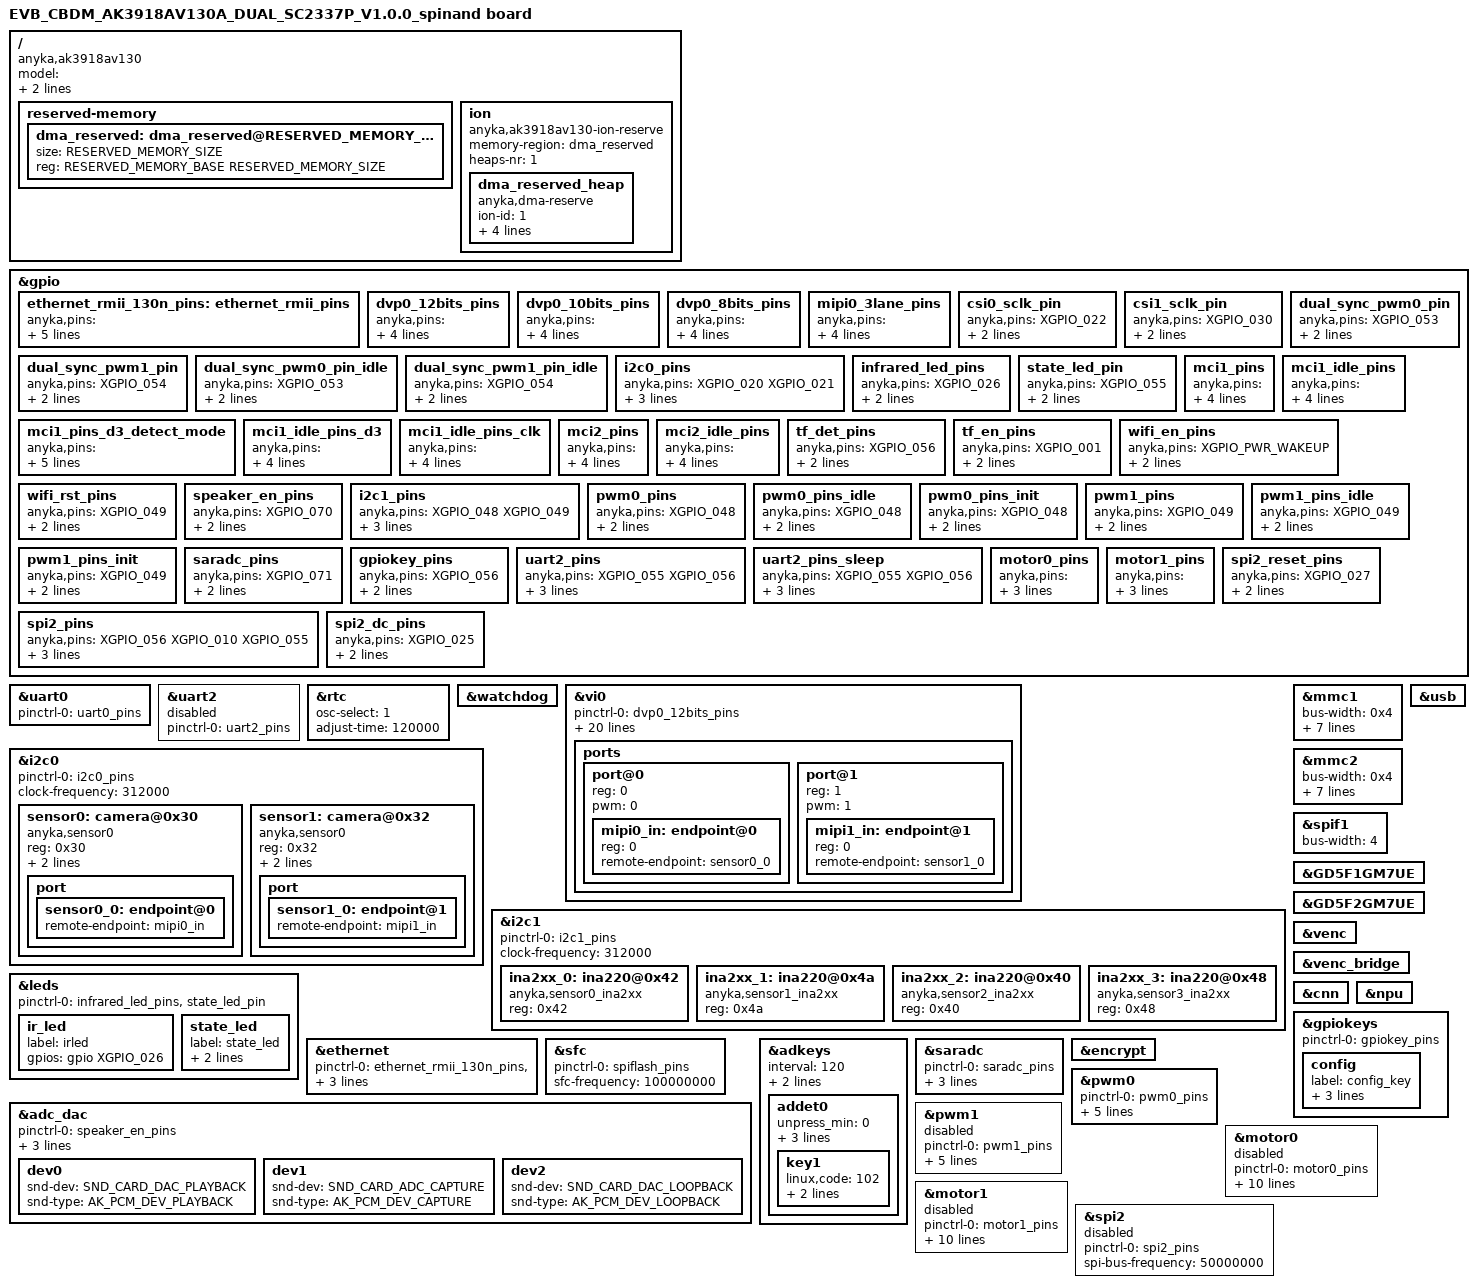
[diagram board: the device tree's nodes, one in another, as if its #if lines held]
/*
 * AK3918AV130 dev board dts
 *
 * Copyright (C) 2020 Anyka(Guangzhou) Microelectronics Technology Co., Ltd.
 *
 * This program is free software; you can redistribute it and/or modify
 * it under the terms of the GNU General Public License as published by
 * the Free Software Foundation; either version 2 of the License, or
 * (at your option) any later version.
 *
 * This program is distributed in the hope that it will be useful,
 * but WITHOUT ANY WARRANTY; without even the implied warranty of
 * MERCHANTABILITY or FITNESS FOR A PARTICULAR PURPOSE.  See the
 * GNU General Public License for more details.
 */

#include "anycloud_ak3918av130.dtsi"
//#include "anycloud_norflash.dtsi"
#include "anycloud_nandflash.dtsi"

#ifdef RESERVED_MEMORY_SIZE
#undef RESERVED_MEMORY_SIZE
#endif

#define RESERVED_MEMORY_SIZE  0x1C00000   /* 28MB*/

/ {
    compatible = "anyka,ak3918av130";
    model = "EVB_CBDM_AK3918AV130A_DUAL_SC2337P_V1.0.0_spinand board";
    version = "V1.0.00";

    reserved-memory {
        #address-cells = <1>;
        #size-cells = <1>;
        ranges;

        dma_reserved: dma_reserved@RESERVED_MEMORY_BASE {
            /*compatible = "shared-dma-pool";*/
            /*linux,cma-default;*/
            /*reusable;*/
            size = <RESERVED_MEMORY_SIZE>;
            reg = <RESERVED_MEMORY_BASE RESERVED_MEMORY_SIZE>;
            status = "okay";
        };

    };

    ion {
        compatible = "anyka,ak3918av130-ion-reserve";
        memory-region = <&dma_reserved>;
        #address-cells = <1>;
        #size-cells = <1>;
        heaps-nr = <1>;
        ranges;

        dma_reserved_heap: dma_reserved_heap {
            compatible = "anyka,dma-reserve";
            ion-id = <1>;
            /* ion-type: 0 = cma ; 1 = prereserved memory which kernel do not  aware of */
            ion-type = <1>;
            base-address = <RESERVED_MEMORY_BASE>;
            size = <RESERVED_MEMORY_SIZE>;
            align = <0x4>;
            status = "okay";
        };
    };
};

&gpio {
    /*
    * "anyka,function": func index, please refer to dt-bindings/pinctrl/ak3918av130_pinctrl.h
    * "anyka,pull": configuration of the pins
    * bit[7:0]: pull up/down configuration
    *     bit[0]: pull up or pull down selection, 1 means select pull down, 0 means select pull up
    *     bit[4]: pull up or pull down enable, 1 means enable pull up&down function, 0 means disable fuction
    * !!! Notice that not all pin support pull up and pull down. Please refer to the programer's guide.
    * bit[11:8]: driver strength configuration.
    *     bit[9:8] drive strength.
    * bit[12:15] gpio direction
    *     bit[12]: direction. 0 is output, 1 is input
    *     bit[15]: enable direction. 1 is enable
    * bit[19:16]: input enable configuration
    *     bit[16]: 1 means enable input, 0 means disable input.
    * bit[20-23]: gpio output level
    *     bit[20]: 0 is low level, 1 is high level
    *     bit[23]: enable gpio output level. 1 is enable
    * bit[31:24]: pin slew rate configuration
    *     bit[24]: 1 means enable slew rate, 0 means disable slew rate.
    * !!! Notice OTHER bits which not mentioned please set to 0.
    */

    ethernet_rmii_130n_pins: ethernet_rmii_pins {
        anyka,pins = <  XGPIO_003
                        XGPIO_005
                        XGPIO_002
                        XGPIO_011
                        XGPIO_006
                        XGPIO_000
                        XGPIO_007
                        XGPIO_008
                        XGPIO_004>;
        anyka,function = <  XGPIO_003_FUNC_RMII_MDIO
                            XGPIO_005_FUNC_RMII_MDC
                            XGPIO_002_FUNC_RMII_RXDV
                            XGPIO_011_FUNC_RMII_RXD0
                            XGPIO_006_FUNC_RMII_RXD1
                            XGPIO_000_FUNC_OPCLK1
                            XGPIO_007_FUNC_RMII_TXD0
                            XGPIO_008_FUNC_RMII_TXD1
                            XGPIO_004_FUNC_RMII_TXEN
                            >;
      anyka,pull = < 0x00010010 /* XGPIO_003_FUNC_RMII_MDIO, input enable, driver 2mA, slow slew rate, pull up enable*/
                     0x00010011 /* XGPIO_005_FUNC_RMII_MDC,  input enable, driver 2mA, slow slew rate, pull down enable*/
                     0x00010011 /* XGPIO_002_FUNC_RMII_RXDV, input enable, driver 2mA, slow slew rate, pull down enable*/
                     0x00010011 /* XGPIO_011_FUNC_RMII_RXD0, input enable, driver 2mA, slow slew rate, pull down enable*/
                     0x00010011 /* XGPIO_006_FUNC_RMII_RXD1, input enable, driver 2mA, slow slew rate, pull down enable*/ 
                     0x00010200 /* XGPIO_000_FUNC_OPCLK1,    input enable, driver 4mA, slow slew rate, pull up disable and pull down disable*/ 
                     0x01010011 /* XGPIO_007_FUNC_RMII_TXD0, input enable, driver 2mA, fast slew rate, pull down enable*/ 
                     0x01010011 /* XGPIO_008_FUNC_RMII_TXD1, input enable, driver 2mA, fast slew rate, pull down enable*/ 
                     0x00010011 /* XGPIO_004_FUNC_RMII_TXEN, input enable, driver 2mA, slow slew rate, pull down enable*/ 
                    >;
    };

    dvp0_12bits_pins: dvp0_12bits_pins {
        anyka,pins = <XGPIO_022
                         XGPIO_100
                         XGPIO_009
                         XGPIO_010
                         XGPIO_017
                         XGPIO_018
                         XGPIO_019
                         XGPIO_020
                         XGPIO_023
                         XGPIO_021
                         XGPIO_022
                         XGPIO_099
                         XGPIO_102
                         XGPIO_101
                         XGPIO_078
                         XGPIO_079>;
        anyka,function = <XGPIO_022_FUNC_CSI0_SCLK
                            XGPIO_100_FUNC_CSI_CLK
                            XGPIO_009_FUNC_CSI_HSYNC
                            XGPIO_010_FUNC_CSI_VSYNC
                            XGPIO_017_FUNC_CSI_D0
                            XGPIO_018_FUNC_CSI_D1
                            XGPIO_019_FUNC_CSI_D2
                            XGPIO_020_FUNC_CSI_D3
                            XGPIO_023_FUNC_CSI_D4
                            XGPIO_021_FUNC_CSI_D5
                            XGPIO_022_FUNC_CSI_D6
                            XGPIO_099_FUNC_CSI_D7
                            XGPIO_102_FUNC_CSI_D8
                            XGPIO_101_FUNC_CSI_D9
                            XGPIO_078_FUNC_CSI_D10
                            XGPIO_079_FUNC_CSI_D11>;
        anyka,pull = <0x00010010>;
    };

    dvp0_10bits_pins: dvp0_10bits_pins {
        anyka,pins = <XGPIO_100		//pclk
                         XGPIO_009	//hsync
                         XGPIO_010	//vsync
                         XGPIO_019	//d2
                         XGPIO_020	//d3
                         XGPIO_023	//d4
                         XGPIO_021	//d5
                         XGPIO_022	//d6
                         XGPIO_099	//d7
                         XGPIO_102	//d8
                         XGPIO_101	//d9
                         XGPIO_078	//d10
                         XGPIO_079>;//d11
        anyka,function = <XGPIO_100_FUNC_CSI_CLK
                            XGPIO_009_FUNC_CSI_HSYNC
                            XGPIO_010_FUNC_CSI_VSYNC
                            XGPIO_019_FUNC_CSI_D2
                            XGPIO_020_FUNC_CSI_D3
                            XGPIO_023_FUNC_CSI_D4
                            XGPIO_021_FUNC_CSI_D5
                            XGPIO_022_FUNC_CSI_D6
                            XGPIO_099_FUNC_CSI_D7
                            XGPIO_102_FUNC_CSI_D8
                            XGPIO_101_FUNC_CSI_D9
                            XGPIO_078_FUNC_CSI_D10
                            XGPIO_079_FUNC_CSI_D11>;
        anyka,pull = <0x00010010>;
    };

    dvp0_8bits_pins: dvp0_8bits_pins {
        anyka,pins = <XGPIO_022
                         XGPIO_100
                         XGPIO_009
                         XGPIO_010
                         XGPIO_017
                         XGPIO_018
                         XGPIO_019
                         XGPIO_020
                         XGPIO_023
                         XGPIO_021
                         XGPIO_022
                         XGPIO_099>;
        anyka,function = <XGPIO_022_FUNC_CSI0_SCLK
                            XGPIO_100_FUNC_CSI_CLK
                            XGPIO_009_FUNC_CSI_HSYNC
                            XGPIO_010_FUNC_CSI_VSYNC
                            XGPIO_017_FUNC_CSI_D0
                            XGPIO_018_FUNC_CSI_D1
                            XGPIO_019_FUNC_CSI_D2
                            XGPIO_020_FUNC_CSI_D3
                            XGPIO_023_FUNC_CSI_D4
                            XGPIO_021_FUNC_CSI_D5
                            XGPIO_022_FUNC_CSI_D6
                            XGPIO_099_FUNC_CSI_D7>;
        anyka,pull = <0x00010010>;
    };

    mipi0_3lane_pins: mipi0_3lane_pins {
        anyka,pins = <XGPIO_099
                        XGPIO_100
                        XGPIO_078
                        XGPIO_079
                        XGPIO_101
                        XGPIO_102>;
        anyka,function = <XGPIO_099_FUNC_MIPI_RX_L0P
                            XGPIO_100_FUNC_MIPI_RX_L0N
                            XGPIO_078_FUNC_MIPI_RX_L1P
                            XGPIO_079_FUNC_MIPI_RX_L1N
                            XGPIO_101_FUNC_MIPI_RX_L2P
                            XGPIO_102_FUNC_MIPI_RX_L2N>;
        anyka,pull = <0x00010010>;
    };

    csi0_sclk_pin: csi0_sclk_pin {
        anyka,pins = <XGPIO_022>;
        anyka,function = <XGPIO_022_FUNC_CSI0_SCLK>;
        anyka,pull = <0x00010010>;
    };

    csi1_sclk_pin: csi1_sclk_pin {
        anyka,pins = <XGPIO_030>;
        anyka,function = <XGPIO_030_FUNC_CSI1_SCLK>;
        anyka,pull = <0x00010010>;
    };

    dual_sync_pwm0_pin: dual_sync_pwm0_pin {
        anyka,pins = <XGPIO_053>;
        anyka,function = <XGPIO_053_FUNC_PWM_CSI0>;
        anyka,pull = <0x01000000>;
    };

    dual_sync_pwm1_pin: dual_sync_pwm1_pin {
        anyka,pins = <XGPIO_054>;
        anyka,function = <XGPIO_054_FUNC_PWM_CSI1>;
        anyka,pull = <0x01000000>;
    };

    dual_sync_pwm0_pin_idle: dual_sync_pwm0_pin_idle {
        anyka,pins = <XGPIO_053>;
        anyka,function = <XGPIO_053_FUNC_GPIO53>;
        anyka,pull = <0x00008011>;
    };

    dual_sync_pwm1_pin_idle: dual_sync_pwm1_pin_idle {
        anyka,pins = <XGPIO_054>;
        anyka,function = <XGPIO_054_FUNC_GPIO54>;
        anyka,pull = <0x00008011>;
    };

    i2c0_pins: i2c0_pins {
        anyka,pins = <XGPIO_020 XGPIO_021>;
        anyka,function = <XGPIO_020_FUNC_TWI0_SDA XGPIO_021_FUNC_TWI0_SCL>;
        anyka,pull = <0x10010>;
    };

    infrared_led_pins: infrared_led_pins {
        anyka,pins = <XGPIO_026>;
        anyka,function = <XGPIO_026_FUNC_GPIO26>;
        anyka,pull = <0x10>;
    };

    state_led_pin: state_led_pin {
        anyka,pins = <XGPIO_055>;
        anyka,function = <XGPIO_055_FUNC_GPIO55>;
        anyka,pull = <0x10>;
    };

    mci1_pins: mci1_pins {
        anyka,pins = <XGPIO_036
                        XGPIO_035
                        XGPIO_034
                        XGPIO_033
                        XGPIO_032
                        XGPIO_031>;
        anyka,function = <XGPIO_036_FUNC_SDIO0_DATA1
                            XGPIO_035_FUNC_SDIO0_DATA0
                            XGPIO_034_FUNC_SDIO0_MCLK
                            XGPIO_033_FUNC_SDIO0_CMD
                            XGPIO_032_FUNC_SDIO0_DATA3
                            XGPIO_031_FUNC_SDIO0_DATA2>;
        anyka,pull = <0x10010>;
    };

    /*
       when not use tf card, set to idle state,
       to protect tf card and extend it's life.
    */
    mci1_idle_pins: mci1_idle_pins {
        anyka,pins = <XGPIO_036
                        XGPIO_035
                        XGPIO_034
                        XGPIO_033
                        XGPIO_032
                        XGPIO_031>;
        anyka,function = <XGPIO_036_FUNC_GPIO36
                            XGPIO_035_FUNC_GPIO35
                            XGPIO_034_FUNC_GPIO34
                            XGPIO_033_FUNC_GPIO33
                            XGPIO_032_FUNC_GPIO32
                            XGPIO_031_FUNC_GPIO31>;
        anyka,pull = <0x11>;
    };

    /* 
     *  When using DATA3 as plugin and plugoff detect:
     *  1. Set XGPIO_032_FUNC_SDIO0_DATA3 pull up disable and pull down disable
     *  2. Using PULLDOWN RESISTANCE on PCB, for example, 510   KΩ.
     */
    mci1_pins_d3_detect_mode: mci1_pins_d3_detect_mode {
        anyka,pins = <XGPIO_036
                        XGPIO_035
                        XGPIO_034
                        XGPIO_033
                        XGPIO_032
                        XGPIO_031>;
        anyka,function = <XGPIO_036_FUNC_SDIO0_DATA1
                            XGPIO_035_FUNC_SDIO0_DATA0
                            XGPIO_034_FUNC_SDIO0_MCLK
                            XGPIO_033_FUNC_SDIO0_CMD
                            XGPIO_032_FUNC_SDIO0_DATA3
                            XGPIO_031_FUNC_SDIO0_DATA2>;
        anyka,pull = <  0x10010 
                        0x10010
                        0x10010
                        0x10010
                        0x10001  /* disable pull down and pull up */
                        0x10010 >;
    };

    /*
       when not use tf card, set to idle state, the pin set to gpio function except dat3 pin.
       to protect tf card, extend it's life.
    */
    mci1_idle_pins_d3: mci1_idle_pins_d3 {
        anyka,pins = <XGPIO_036
                        XGPIO_035
                        XGPIO_034
                        XGPIO_033
                        XGPIO_032
                        XGPIO_031>;
        anyka,function = <XGPIO_036_FUNC_GPIO36
                            XGPIO_035_FUNC_GPIO35
                            XGPIO_034_FUNC_GPIO34
                            XGPIO_033_FUNC_GPIO33
                            XGPIO_032_FUNC_SDIO0_DATA3
                            XGPIO_031_FUNC_GPIO31>;
        anyka,pull = <  0x11
                        0x11
                        0x11
                        0x11
                        0x10001  /* disable pull down and pull up */
                        0x11 >;
    };

    /*
       when not use tf card, set to idle state, the pin set to gpio function except mclk pin.
       to protect tf card, extend it's life.
    */
    mci1_idle_pins_clk: mci1_idle_pins_clk {
        anyka,pins = <XGPIO_036
                        XGPIO_035
                        XGPIO_034
                        XGPIO_033
                        XGPIO_032
                        XGPIO_031>;
        anyka,function = <XGPIO_036_FUNC_GPIO36
                            XGPIO_035_FUNC_GPIO35
                            XGPIO_034_FUNC_SDIO0_MCLK
                            XGPIO_033_FUNC_GPIO33
                            XGPIO_032_FUNC_GPIO32
                            XGPIO_031_FUNC_GPIO31>;
        anyka,pull = <  0x11
                        0x11
                        0x10010 /* clk */
                        0x11
                        0x11
                        0x11 >;
    };

    mci2_pins: mci2_pins {
        anyka,pins = <XGPIO_058
                     XGPIO_065
                     XGPIO_066
                     XGPIO_067
                     XGPIO_068
                     XGPIO_069>;
        anyka,function = <  XGPIO_058_FUNC_SDIO1_CMD
                        XGPIO_065_FUNC_SDIO1_MCLK
                        XGPIO_066_FUNC_SDIO1_DATA2
                        XGPIO_067_FUNC_SDIO1_DATA3
                        XGPIO_068_FUNC_SDIO1_DATA0
                        XGPIO_069_FUNC_SDIO1_DATA1>;
        anyka,pull = <0x10010>;
    };

    mci2_idle_pins: mci2_idle_pins {
        anyka,pins = <  XGPIO_058
                        XGPIO_065
                        XGPIO_066
                        XGPIO_067
                        XGPIO_068
                        XGPIO_069>;
        anyka,function = <  XGPIO_058_FUNC_GPIO58
                            XGPIO_065_FUNC_GPIO65
                            XGPIO_066_FUNC_GPIO66
                            XGPIO_067_FUNC_GPIO67
                            XGPIO_068_FUNC_GPIO68
                            XGPIO_069_FUNC_GPIO69>;
        anyka,pull = <0x0>;

    };

    tf_det_pins: tf_det_pins {
        anyka,pins = <XGPIO_056>;
        anyka,function = <XGPIO_056_FUNC_GPIO56>;
        anyka,pull = <0x10010>;
    };

    tf_en_pins: tf_en_pins {
        anyka,pins = <XGPIO_001>;
        anyka,function = <XGPIO_001_FUNC_GPIO1>;
        anyka,pull = <0x10010>;
    };

    wifi_en_pins: wifi_en_pins {
        anyka,pins = <XGPIO_PWR_WAKEUP>;
        anyka,function = <XGPIO_081_FUNC_GPIO81>;
        anyka,pull = <0x10010>;
    };

    wifi_rst_pins: wifi_rst_pins {
        anyka,pins = <XGPIO_049>;
        anyka,function = <XGPIO_049_FUNC_GPIO49>;
        anyka,pull = <0x10010>;
    };

    speaker_en_pins: speaker_en_pins {
        anyka,pins = <XGPIO_070>;
        anyka,function = <XGPIO_070_FUNC_GPIO70>;
        anyka,pull = <0x00808000>;
    };

    i2c1_pins: i2c1_pins {
        anyka,pins = <XGPIO_048 XGPIO_049>;
        anyka,function = <XGPIO_048_FUNC_TWI1_SCL XGPIO_049_FUNC_TWI1_SDA>;
        anyka,pull = <0x10010>;
    };

    pwm0_pins: pwm0_pins {
        anyka,pins = <XGPIO_048>;
        anyka,function = <XGPIO_048_FUNC_PWM0>;
        anyka,pull = <0x1000010>;
    };

    pwm0_pins_idle: pwm0_pins_idle {
        anyka,pins = <XGPIO_048>;
        anyka,function = <XGPIO_048_FUNC_GPIO48>;
        anyka,pull = <0x00808000>;
    };

    pwm0_pins_init: pwm0_pins_init {
        anyka,pins = <XGPIO_048>;
        anyka,function = <XGPIO_048_FUNC_GPIO48>;
        anyka,pull = <0x00019010>;
    };

    pwm1_pins: pwm1_pins {
        anyka,pins = <XGPIO_049>;
        anyka,function = <XGPIO_049_FUNC_PWM1>;
        anyka,pull = <0x1000010>;
    };

    pwm1_pins_idle: pwm1_pins_idle {
        anyka,pins = <XGPIO_049>;
        anyka,function = <XGPIO_049_FUNC_GPIO49>;
        anyka,pull = <0x00808000>;
    };

    pwm1_pins_init: pwm1_pins_init {
        anyka,pins = <XGPIO_049>;
        anyka,function = <XGPIO_049_FUNC_GPIO49>;
        anyka,pull = <0x00019010>;
    };

    saradc_pins: saradc_pins {
        anyka,pins = <XGPIO_071>;
        anyka,function = <XGPIO_071_FUNC_AIN0>;
        anyka,pull = <0x0000000>;
    };

	gpiokey_pins:gpiokey_pins {
		anyka,pins = <XGPIO_056>;
		anyka,function = <XGPIO_056_FUNC_GPIO56>;
		anyka,pull = <0x00010010>;
	};

    uart2_pins: uart2_pins {
        /* uart1 without flow control */
        anyka,pins = <XGPIO_055 XGPIO_056>;
        anyka,function = <XGPIO_055_FUNC_UART2_RXD XGPIO_056_FUNC_UART2_TXD>;
        anyka,pull = <0x00010010 0x00010010>;
    };

    uart2_pins_sleep: uart2_pins_sleep {
        /* uart1 without flow control */
        anyka,pins = <XGPIO_055 XGPIO_056>;
        anyka,function = <XGPIO_055_FUNC_GPIO55 XGPIO_056_FUNC_GPIO56>;
        anyka,pull = <0x00000000>;
    };

    /* function: 0 means gpio */
    motor0_pins: motor0_pins {
        anyka,pins = <XGPIO_048 XGPIO_049 XGPIO_003 XGPIO_002>;
        anyka,function = <0>;
        anyka,pull = <0x00000010>;
    };

    motor1_pins: motor1_pins {
        anyka,pins = <XGPIO_001 XGPIO_000 XGPIO_055 XGPIO_056>;
        anyka,function = <0>;
        anyka,pull = <0x00000010>;
    };

    spi2_pins: spi2_pins {
        anyka,pins = <XGPIO_056 XGPIO_010 XGPIO_055>;
        anyka,function = <XGPIO_056_FUNC_SPI2_CLK XGPIO_010_FUNC_SPI2_DOUT XGPIO_055_FUNC_SPI2_CS0>;
        anyka,pull = <0x00010000>;
    };
    
    spi2_reset_pins: spi2_reset_pins {
        anyka,pins = <XGPIO_027>;
        anyka,function = <XGPIO_027_FUNC_GPIO27>;
        anyka,pull = <0x00010010>;
    };
    
    spi2_dc_pins: spi2_dc_pins {
        anyka,pins = <XGPIO_025>;
        anyka,function = <XGPIO_025_FUNC_GPIO25>;
        anyka,pull = <0x00010010>;
    };
    
};

&uart0 {
    pinctrl-names = "default";
    pinctrl-0 = <&uart0_pins>;
    status = "okay";
};

&uart2 {
    pinctrl-names = "default";
    pinctrl-0 = <&uart2_pins>;
    status = "disable";
};

&rtc {
    /*
     * rtc osc-select, 1 means INTERNAL RC OSC, 0 means EXTERNAL XTAL
     * if internal RC OSC is used to generate 32KH,time adjustment should be setting.(basic unit: ms)
     * AV100P/X only support internal RC OSC.
     */
    osc-select = <1>;
    adjust-time = <120000>;//校准间隔时间单位ms
    status = "okay";
};


&watchdog {
    status = "okay";
};

&vi0{
    pinctrl-names = "dvp0_12bits", "dvp0_10bits", "dvp0_8bits",
                    /*
                    * "mipi0_2lane", "mipi0_1lane",
                    */
                    "csi0_sclk", "csi1_sclk",
                    "pwm0", "pwm1",
                    "pwm0_idle", "pwm1_idle";
    pinctrl-0 = <&dvp0_12bits_pins>;
    pinctrl-1 = <&dvp0_10bits_pins>;
    pinctrl-2 = <&dvp0_8bits_pins>;
    pinctrl-3 = <&csi0_sclk_pin>;
    pinctrl-4 = <&csi1_sclk_pin>;
    pinctrl-5 = <&dual_sync_pwm0_pin>;
    pinctrl-6 = <&dual_sync_pwm1_pin>;
	pinctrl-7 = <&dual_sync_pwm0_pin_idle>;
	pinctrl-8 = <&dual_sync_pwm1_pin_idle>;

	/*
    pinctrl-5 = <&mipi0_2lane_pins>;
    pinctrl-6 = <&mipi0_1lane_pins>;
	*/
    status = "okay";

	csi_mipi_lane_swap = <
		SENSOR_D0	//L0
		SENSOR_C0	//L1
		SENSOR_D1	//L2
        SENSOR_D2   //L3
        SENSOR_C1   //L4
        SENSOR_D3   //L5
		>;//MIPI_RX_L0~2.
	csi_mipi_dndp_swap = <
		MIPI_DNDP_NOSWAP	//L0
		MIPI_DNDP_NOSWAP	//L1
		MIPI_DNDP_NOSWAP	//L2
	>;//MIPI_RX_L0~2. 0: noswap; others: swap

    clocks =  
                /*<&factor_pll3_clk  PLL3_FACTOR_ISP>,*/
                /*<&factor_pll2_clk  PLL2_FACTOR_ISP>,*/
                <&isp_mux_clk>,
                <&gclk GCLK_MIPI0>,
                <&gclk GCLK_MIPI1>,
                <&factor_osc24    OSC24_FACTOR_CSI0_SCLK>,
                <&factor_osc24    OSC24_FACTOR_CSI1_SCLK>,
                <&factor_pll1_clk  PLL1_FACTOR_ISP>,
                <&factor_pll2_clk  PLL2_FACTOR_ISP>,
                <&factor_pll3_clk  PLL3_FACTOR_ISP>,
                <&factor_pll2_clk PLL2_FACTOR_DPHY_CFGCLK>;
    clock-names =   "isp_clk", 
                    "mipi0_gclk",
                    "mipi1_gclk",
                    "csi0_sclk",
                    "csi1_sclk",
                    "pll1_isp", 
                    "pll2_isp", 
                    "pll3_isp",
                    "pll2_dphy";

    ports {
        #address-cells = <1>;
        #size-cells = <0>;

        port@0 {
            #address-cells = <1>;
            #size-cells = <0>;
            reg = <0>; //mipi0
            pwm = <0>;

            mipi0_in: endpoint@0 {
                reg = <0>;
                remote-endpoint = <&sensor0_0>;
            };
        };

        port@1 {
            #address-cells = <1>;
            #size-cells = <0>;
            reg = <1>; //mipi1
            pwm = <1>;

            mipi1_in: endpoint@1 {
                reg = <0>;
                remote-endpoint = <&sensor1_0>;
            };
        };
    };
};

&i2c0 {
    pinctrl-names = "default";
    pinctrl-0 = <&i2c0_pins>;

    clock-frequency = <312000>;
    status = "okay";
	#address-cells = <1>;
	#size-cells = <0>;

	sensor0: camera@0x30{
		compatible = "anyka,sensor0";
		reg = <0x30>;

		/*0xffff means the gpio is invalid*/
		reset-gpio = <&gpio XGPIO_018 1>;
		pwdn-gpio = <&gpio XGPIO_048 1>;

		port {
			sensor0_0: endpoint@0 {
				remote-endpoint = <&mipi0_in>;
			};
		};
	};

	sensor1: camera@0x32{
		compatible = "anyka,sensor0";
		reg = <0x32>;

		/*0xffff means the gpio is invalid*/
		reset-gpio = <&gpio XGPIO_019 1>;
		pwdn-gpio = <&gpio XGPIO_049 1>;

		port {
			sensor1_0: endpoint@1 {
				remote-endpoint = <&mipi1_in>;
			};
		};
	};
};

#ifdef AK_PWR_CONSUMPTION_TEST
&i2c1 {
    pinctrl-names = "default";
    pinctrl-0 = <&i2c1_pins>;
    clock-frequency = <312000>;
    status = "okay";
	#address-cells = <1>;
	#size-cells = <0>;

	ina2xx_0: ina220@0x42{
		compatible = "anyka,sensor0_ina2xx";
		reg = <0x42>;
	};

	ina2xx_1: ina220@0x4a{
		compatible = "anyka,sensor1_ina2xx";
		reg = <0x4a>;
	};

	ina2xx_2: ina220@0x40{
		compatible = "anyka,sensor2_ina2xx";
		reg = <0x40>;
	};

	ina2xx_3: ina220@0x48{
		compatible = "anyka,sensor3_ina2xx";
		reg = <0x48>;
	};
};
#else
&i2c1 {
    pinctrl-names = "default";
    pinctrl-0 = <&i2c1_pins>;
    clock-frequency = <312000>;
    status = "disable";
	#address-cells = <1>;
	#size-cells = <0>;
};
#endif

&leds {
    pinctrl-names = "default";
    pinctrl-0 = <&infrared_led_pins>,<&state_led_pin>;
    status = "okay";

    ir_led {
        label = "irled";
        gpios = <&gpio XGPIO_026 GPIO_ACTIVE_HIGH>;
    };

    state_led {
        label = "state_led";
        gpios = <&gpio XGPIO_055 GPIO_ACTIVE_HIGH>;
        default-state = "off";
    };
};

/* mmc1 card detect using detect-gpio or detect-gpios */
/*
&mmc1 {
    bus-width = <0x4>;
    max-frequency = <50000000>;
    detect-gpio = <&gpio XGPIO_056 1>; 
    cap-sd-highspeed;
    pinctrl-names = "default","idle";
    pinctrl-0 = <&mci1_pins>,<&tf_en_pins>,<&tf_det_pins>;
    pinctrl-1 = <&mci1_idle_pins>; 
    power-pins = <&gpio XGPIO_001 1>; 
    power-inverted;
    status = "okay"; 
};
*/

/* mmc1 card detect using cd_clk */
&mmc1 {
    bus-width = <0x4>;
    max-frequency = <50000000>;
    cd_clk;
    cap-sd-highspeed;
    pinctrl-names = "default","idle";
    pinctrl-0 = <&mci1_pins>,<&tf_en_pins>;
    pinctrl-1 = <&mci1_idle_pins_clk>;
    power-pins = <&gpio XGPIO_001 1>;
    power-inverted;
    status = "okay"; 
};

/* mmc1 card detect using cd_d3 */
/*
&mmc1 {
    bus-width = <0x4>;
    max-frequency = <50000000>;
    cd_d3;
    cap-sd-highspeed;
    pinctrl-names = "default","idle";
    pinctrl-0 = <&mci1_pins_d3_detect_mode>,<&tf_en_pins>;
    pinctrl-1 = <&mci1_idle_pins_d3>; 
    power-pins = <&gpio XGPIO_001 1>; 
    power-inverted;
    status = "okay"; 
};
*/
&mmc2 {
    bus-width = <0x4>;
    max-frequency = <50000000>;
    non-removable;
    cap-sd-highspeed;
    /* if support sdio, using cap-sdio-irq*/
    cap-sdio-irq;
    pinctrl-names = "default","idle";
    //pinctrl-0 = <&mci2_pins>,<&wifi_en_pins>,<&wifi_rst_pins>;
    pinctrl-0 = <&mci2_pins>,<&wifi_en_pins>;
    pinctrl-1 = <&mci2_idle_pins>;
    power-pins = <&gpio XGPIO_098 1>;   //power-pins is which wifi_en_pins describes
    //rst-pins =   <&gpio XGPIO_026 1>;    //rst-pins is which wifi_rst_pins describes
    status = "okay"; 
};

&ethernet {
    pinctrl-names = "default";
    pinctrl-0 = <&ethernet_rmii_130n_pins &ethernet_rst_pins>;
    reset-gpios = <&gpio XGPIO_024 1>;
	phy-address = <1>;
    status = "okay";
};

&usb {
    status = "okay";
};

&sfc {
    pinctrl-names = "default";
    pinctrl-0 = <&spiflash_pins>;
    sfc-frequency = <100000000>;
    status = "okay";
};

&spif1 {
    /* spi flash data bus width:
    ** 1 means 1 wire mode.
    ** 2 means 2 wire mode
    ** 4 means 4 wire mode.
    ** default: 4 wire mode.
    **/
    bus-width = <4>;
    status = "okay";
};

&GD5F1GM7UE {
    status = "okay";
};

&GD5F2GM7UE {
    status = "okay";
};

&adc_dac {
    pinctrl-names = "default";
    pinctrl-0 = <&speaker_en_pins>;
    speak-gpios = <&gpio XGPIO_070 1>;
    pd-hpvcm = <1>;
    /*
    * The level of speak-gpios votage for power on audio: 0=low, 1=high
    */
    speak-gpios-en = <1>;
    status = "okay";

    dev0 {
        snd-dev = <SND_CARD_DAC_PLAYBACK>;
        snd-type = <AK_PCM_DEV_PLAYBACK>;
    };

    dev1 {
        snd-dev = <SND_CARD_ADC_CAPTURE>;
        snd-type = <AK_PCM_DEV_CAPTURE>;
    };

    dev2 {
        snd-dev = <SND_CARD_DAC_LOOPBACK>;
        snd-type = <AK_PCM_DEV_LOOPBACK>;
    };
};

&venc {
    status = "okay";
};

&venc_bridge{
     status = "okay";
};

&cnn{
    status = "okay";
};

&npu{
    status = "okay";
};

&gpiokeys {
	#address-cells = <1>;
	#size-cells = <0>;
	pinctrl-0 = <&gpiokey_pins>;
	pinctrl-names = "default";
	status = "okay";

	config {
        label = "config_key";
        gpios = <&gpio XGPIO_056 GPIO_ACTIVE_HIGH>;
        linux,code = <116>;
        debounce-interval = <100>;
	};
};

&adkeys {
    /*
    * poll interval: ms
    * debounce interval: ms
    */
    interval = <120>;
    debounce_interval = <20>;
    /*
    * if pressed-input = 0, input 0 when key is pressed, else input 1.
    */
    pressed-input = <0>;
    status = "okay";

    addet0 {
        unpress_min = <0>;
        unpress_max = <3200>;
        adc_index = <1>;
        adc_channel = <0>;

        key1 {
            linux,code = <102>; 
            min = <0>;
            max = <50>;
        };
    };
};

&saradc {
    pinctrl-names = "default";
    pinctrl-0 = <&saradc_pins>;

    /*
	 * SAR ADC VREF selection
     * 	0:To select HPVDD 3.3V as VREF for SAR ADC.
     * 	1:To select 3.0V generated from DDR as VREF for SAR ADC.
     */
    vref-select = <0>;

    /*
     * 0: To disable BAT voltage divider.
     * 1: To enable BAT voltage divider divided by 2.
     */
    battery-divider = <1>;

    /*
     * Sampling number
     * 	Read the sampling data for N times and then calculate the average value.
     * 	N ranges from 1 to 7.
     */
    sampling-num = <3>;
    status = "okay";
};

&encrypt{
    status = "okay"; 
};

&pwm0 {
	pinctrl-names = "default", "idle", "init";
	pinctrl-0 = <&pwm0_pins>;
	pinctrl-1 = <&pwm0_pins_idle>;
    pinctrl-2 = <&pwm0_pins_init>;
	period-ns = <500>;
	duty-ns = <100>;
	pwm-enable = <1>;
	status = "okay";
};

&pwm1 {
	pinctrl-names = "default", "idle", "init";
    pinctrl-0 = <&pwm1_pins>;
    pinctrl-1 = <&pwm1_pins_idle>;
    pinctrl-2 = <&pwm1_pins_init>;
	period-ns = <500>;
	duty-ns = <250>;
	pwm-enable = <1>;
	status = "disable";
};

&motor0 {
	/*
	 * part-number: part name
	 * pwm-tbl-cw: pwm table int clkwise
	 * pwm-pins: gpio list to motor
	 * steps-one-circle: total steps one circle (360degree)
	 *
	 * total-steps:	total steps the motor can run
	 * boundary-steps: reserve some step for each boudary
	 * attach-timer: timer for the motor
	 *					NOTE: different motor attach different timer
	 *
	 * speed-step: speed in step
	 */

	pinctrl-names = "default";
	pinctrl-0 = <&motor0_pins>;

	part-number = "HZF-24BYJ48";
	pwm-tbl-cw = <0x09 0x01 0x03 0x02 0x06 0x04 0x0c 0x08>;
	pwm-pins = <XGPIO_048 XGPIO_049 XGPIO_003 XGPIO_002>;
	steps-one-circle = <4096>;
	total-steps = <2500>;
	boundary-steps = <50>;
	attach-timer = <2>;

	speed-step = <200>;

	status = "disable";
};

&motor1 {
	/*
	 * part-number: part name
	 * pwm-tbl-cw: pwm table int clkwise
	 * pwm-pins: gpio list to motor
	 * steps-one-circle: total steps one circle (360degree)
	 *
	 * total-steps:	total steps the motor can run
	 * boundary-steps: reserve some step for each boudary
	 * attach-timer: timer for the motor
	 *					NOTE: different motor attach different timer
	 *
	 * speed-step: speed in step
	 */

	pinctrl-names = "default";
	pinctrl-0 = <&motor1_pins>;

	part-number = "HZF-24BYJ48";
	pwm-tbl-cw = <0x09 0x01 0x03 0x02 0x06 0x04 0x0c 0x08>;
	pwm-pins = <XGPIO_001 XGPIO_000 XGPIO_055 XGPIO_056>;
	steps-one-circle = <4096>;

	total-steps = <600>;
	boundary-steps = <50>;
	attach-timer = <3>;

	speed-step = <200>;

	status = "disable";
};

&spi2 {
    pinctrl-names = "default";
    pinctrl-0 = <&spi2_pins>;
  
    spi-bus-frequency = <50000000>;
    /*
     * cap-spi-highspeed;
     * if defined, means high speed controller(Maximum 100M/s);
     * if not, means normal speed controller(below 50M/s)
     */
    /* cap-spi-highspeed; */
    status =  "disable";//注意&leds和&uart2的引脚冲突


#if 0
    ili9341@0{
        pinctrl-names = "default";
        /* pinctrl-0 = <&spi1_reset_pins &spi1_dc_pins &spi1_led_pins>; */
        pinctrl-0 = <&spi2_reset_pins &spi2_dc_pins>;
        compatible = "ilitek,ili9341";
        spi-max-frequency = <50000000>;
        reg = <0>;
        status = "okay";
  
        dc-gpios = <&gpio 25 GPIO_ACTIVE_HIGH>;
        reset-gpios = <&gpio 27 GPIO_ACTIVE_LOW>;
        /* led-gpios = <&gpio 98 GPIO_ACTIVE_HIGH>; */
  
        spi-cpol;
        spi-cpha;
  
        width = <240>;
        height = <320>;
        bgr = <1>;
        buswidth = <8>;
        regwidth = <8>;
        rotate = <0>;
        fps = <30>;
        debug = <0>;
    };
#endif


};
